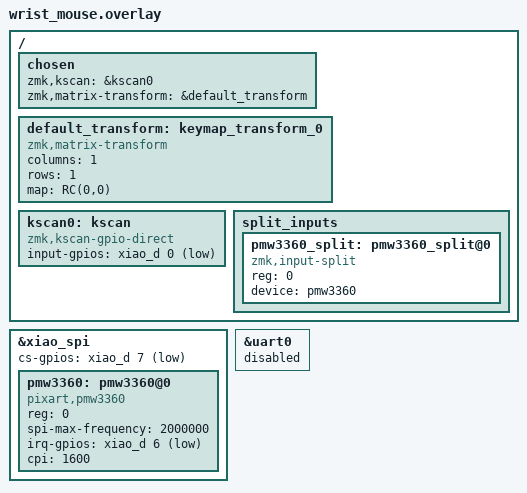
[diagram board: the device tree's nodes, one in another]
/*
 * Copyright (c) 2026 The ZMK Contributors
 * SPDX-License-Identifier: MIT
 */

#include <dt-bindings/zmk/matrix_transform.h>
#include <zephyr/dt-bindings/input/input-event-codes.h>

/ {
    chosen {
        zmk,kscan = &kscan0;
        zmk,matrix-transform = &default_transform;
    };

    default_transform: keymap_transform_0 {
        compatible = "zmk,matrix-transform";
        columns = <1>;
        rows = <1>;
        map = <
            RC(0,0)
        >;
    };

    // Dummy matrix registration since this is a sensor-only device without keys (uses unused D0)
    kscan0: kscan {
        compatible = "zmk,kscan-gpio-direct";
        input-gpios = <&xiao_d 0 (GPIO_ACTIVE_LOW | GPIO_PULL_UP)>;
    };
};

&xiao_spi {
    status = "okay";
    cs-gpios = <&xiao_d 7 GPIO_ACTIVE_LOW>;

    pmw3360: pmw3360@0 {
        compatible = "pixart,pmw3360";
        reg = <0>;
        spi-max-frequency = <2000000>;
        irq-gpios = <&xiao_d 6 (GPIO_ACTIVE_LOW | GPIO_PULL_UP)>;
        cpi = <1600>;
        /* Axis inversion if needed (can be adjusted according to wrist orientation) */
        /* invert-x; */
        /* invert-y; */
    };
};

/ {
    split_inputs {
        #address-cells = <1>;
        #size-cells = <0>;

        pmw3360_split: pmw3360_split@0 {
            compatible = "zmk,input-split";
            reg = <0>;
            device = <&pmw3360>;
        };
    };
};

/* Disable UART0 so D6 (IRQ) and D7 (CS) can be used as GPIO pins */
&uart0 {
    status = "disabled";
};
